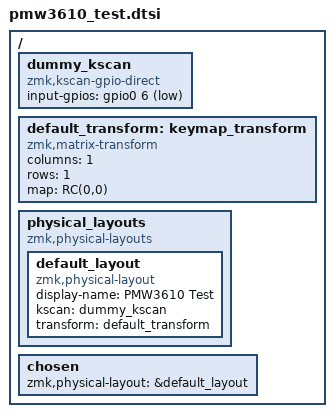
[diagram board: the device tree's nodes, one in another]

#include <dt-bindings/zmk/matrix_transform.h>

/ {
    dummy_kscan: dummy_kscan {
        compatible = "zmk,kscan-gpio-direct";
        input-gpios = <&gpio0 6 (GPIO_ACTIVE_LOW | GPIO_PULL_UP)>;
        status = "okay";
    };

    default_transform: keymap_transform {
        compatible = "zmk,matrix-transform";
        columns = <1>;
        rows = <1>;
        map = <RC(0,0)>;
    };

    physical_layouts {
        compatible = "zmk,physical-layouts";

        default_layout: default_layout {
            compatible = "zmk,physical-layout";
            display-name = "PMW3610 Test";
            kscan = <&dummy_kscan>;
            transform = <&default_transform>;
        };
    };

    chosen {
        zmk,physical-layout = &default_layout;
    };
};
